# K210 register map
Vendor: Canaan Inc.; File version: 1.0
Registers are 32-bit, read-write, reset 0x0 unless marked. A register's access mark holds for its fields unless they carry their own. Offsets are from the block's base; [hi:lo] are bit positions; {n}, {i} and the like mark numbered series; 'fields as' and 'values as' point back to an identical list.

## SPI0 — Serial Peripheral Interface 0 (master)
Base 0x52000000
Same registers: SPI1 0x53000000, SPI3 0x54000000
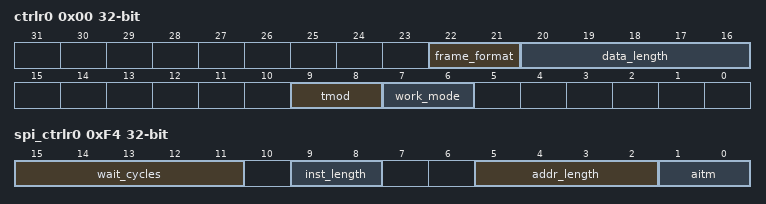
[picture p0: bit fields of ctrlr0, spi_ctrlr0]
0x00 ctrlr0 — Control Register 0
  [22:21] frame_format
    0=standard; 1=dual; 2=quad; 3=octal
  [20:16] data_length range 3..31 — DATA_BIT_LENGTH
  [9:8] tmod — TRANSFER_MODE
    0=trans_recv; 1=trans; 2=recv; 3=eerom
  [7:6] work_mode
    {v}=mode{v} (v=0..3)
0x04 ctrlr1 — Control Register 1
0x08 ssienr — Enable Register
0x0C mwcr — Microwire Control Register
0x10 ser — Slave Enable Register
0x14 baudr — Baud Rate Select
0x18 txftlr — Transmit FIFO Threshold Level
0x1C rxftlr — Receive FIFO Threshold Level
0x20 txflr — Transmit FIFO Level Register
0x24 rxflr — Receive FIFO Level Register
0x28 sr — Status Register
0x2C imr — Interrupt Mask Register
0x30 isr — Interrupt Status Register
0x34 risr — Raw Interrupt Status Register
0x38 txoicr — Transmit FIFO Overflow Interrupt Clear Register
0x3C rxoicr — Receive FIFO Overflow Interrupt Clear Register
0x40 rxuicr — Receive FIFO Underflow Interrupt Clear Register
0x44 msticr — Multi-Master Interrupt Clear Register
0x48 icr — Interrupt Clear Register
0x4C dmacr — DMA Control Register
0x50 dmatdlr — DMA Transmit Data Level
0x54 dmardlr — DMA Receive Data Level
0x58 idr — Identification Register
0x5C ssic_version_id — DWC_ssi component version
{0x60+4i} dr{i} (i=0..35) — Data Register
0xF0 rx_sample_delay
0xF4 spi_ctrlr0 — SPI Control Register
  [15:11] wait_cycles
  [9:8] inst_length — INSTRUCTION_LENGTH
  [5:2] addr_length
  [1:0] aitm — instruction_address_trans_mode
    0=standard; 1=addr_standard; 2=as_frame_format
0xFC xip_mode_bits
0x100 xip_incr_inst — XIP INCR transfer opcode
0x104 xip_wrap_inst — XIP WRAP transfer opcode
0x108 xip_ctrl — XIP Control Register
0x10C xip_ser — XIP Slave Enable Register
0x110 xrxoicr — XIP Receive FIFO Overflow Interrupt Clear Register
0x114 xip_cnt_time_out — XIP time out register for continuous transfers
0x118 endian

## SPI2 — Serial Peripheral Interface 2 (slave)
Base 0x50240000
Same registers: OTP 0x50420000
0x00 dummy — Dummy register: this peripheral is not implemented yet

## APU — Audio Processor
Base 0x50250200
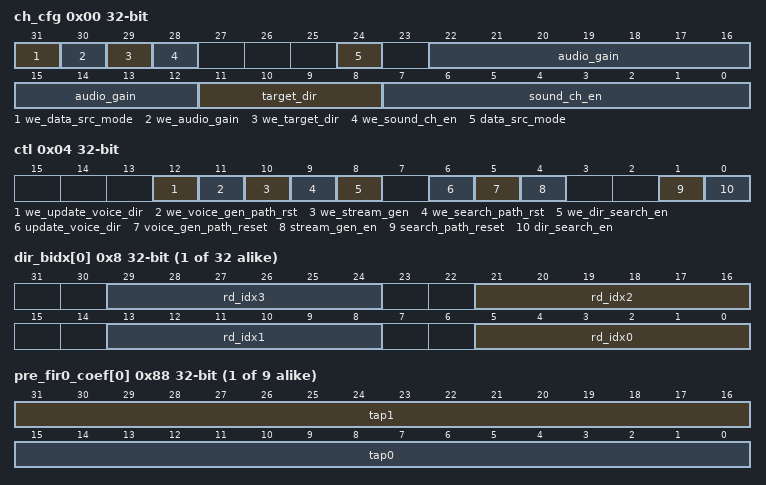
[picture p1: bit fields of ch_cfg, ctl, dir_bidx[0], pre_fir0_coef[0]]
0x00 ch_cfg — Channel Config Register
  [31] we_data_src_mode wo — Write enable for data_out_mode parameter
  [30] we_audio_gain wo — Write enable for audio_gain parameter
  [29] we_target_dir wo — Write enable for target_dir parameter
  [28] we_sound_ch_en wo — Write enable for sound_ch_en parameter
  [24] data_src_mode — Audio data source configure parameter
  [22:12] audio_gain — Audio sample gain factor
  [11:8] target_dir — Target direction select for valid voice output
  [7:0] sound_ch_en — BF unit sound channel enable control bits
0x04 ctl — Control Register
  [12] we_update_voice_dir wo — Write enable for we_update_voice_dir parameter
  [11] we_voice_gen_path_rst wo — Write enable for we_voice_gen_path_rst parameter
  [10] we_stream_gen wo — Write enable for we_stream_gen parameter
  [9] we_search_path_rst wo — Write enable for we_search_path_rst parameter
  [8] we_dir_search_en wo — Write enable for we_dir_search_en parameter
  [6] update_voice_dir — Switch to a new voice source direction
  [5] voice_gen_path_reset — Reset all control logic on voice stream generating path
  [4] stream_gen_en — Valid voice sample stream generation enable bit
  [1] search_path_reset — Reset all control logic on direction search processing path
  [0] dir_search_en — Sound direction searching enable bit
{0x8+4i} dir_bidx[{i}] (i=0..31) — Direction Sample Buffer Read Index Configure Register (16 directions * 2 values * 4 indices)
  [8n+5:8n] rd_idx{n} (n=0..3) — rd_idx{n}
{0x88+4i} pre_fir0_coef[{i}] (i=0..8) — FIR0 pre-filter coefficients
  [31:16] tap1, [15:0] tap0
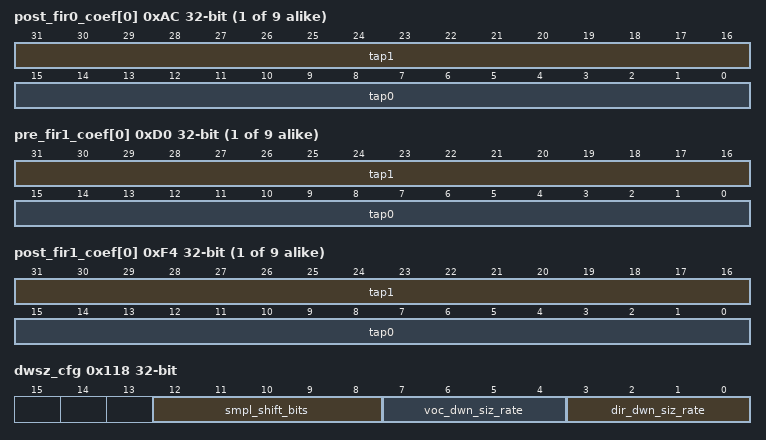
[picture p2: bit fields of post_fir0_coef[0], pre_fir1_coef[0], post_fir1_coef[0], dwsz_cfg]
{0xAC+4i} post_fir0_coef[{i}] (i=0..8) — FIR0 post-filter coefficients
  [31:16] tap1, [15:0] tap0
{0xD0+4i} pre_fir1_coef[{i}] (i=0..8) — FIR1 pre-filter coeffecients
  [31:16] tap1, [15:0] tap0
{0xF4+4i} post_fir1_coef[{i}] (i=0..8) — FIR1 post-filter coefficients
  [31:16] tap1, [15:0] tap0
0x118 dwsz_cfg — Downsize Config Register
  [12:8] smpl_shift_bits — Sample precision reduction when the source sound sample precision is 20/24/32 bits
  [7:4] voc_dwn_siz_rate — Down-sizing ratio used for voice stream generation
  [3:0] dir_dwn_siz_rate — Down-sizing ratio used for direction searching
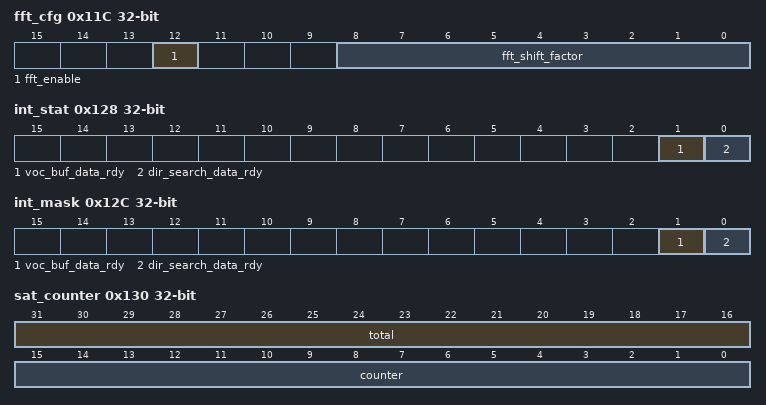
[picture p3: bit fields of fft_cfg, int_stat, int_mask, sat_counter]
0x11C fft_cfg — FFT Config Register
  [12] fft_enable, [8:0] fft_shift_factor
0x120 sobuf_dma_rdata — Read register for DMA to sample-out buffers
0x124 vobuf_dma_rdata — Read register for DMA to voice-out buffers
0x128 int_stat — Interrupt Status Register
  [1] voc_buf_data_rdy — Voice output stream buffer data ready interrupt event
  [0] dir_search_data_rdy — Sound direction searching data ready interrupt event
0x12C int_mask — Interrupt Mask Register
  fields as int_stat
0x130 sat_counter — Saturation Counter
  [31:16] total, [15:0] counter
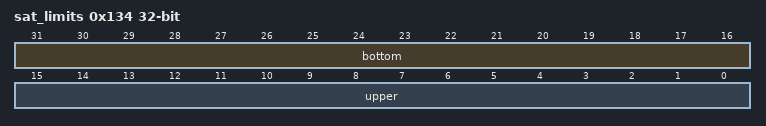
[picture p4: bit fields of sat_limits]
0x134 sat_limits — Saturation Limits
  [31:16] bottom — Bottom limit
  [15:0] upper — Upper limit
